# SPGSS1_1.0 register map
Vendor: Texas Instruments
Registers are 32-bit, read-write, no defined reset value unless marked. A register's access mark holds for its fields unless they carry their own. Offsets are as the file gives them; [hi:lo] are bit positions; lines under a group give offsets from that group; {n}, {i} and the like mark numbered series; 'fields as' and 'values as' point back to an identical list; <NAME> marks a mode.

## SPGSS1 (part 8 of 8)
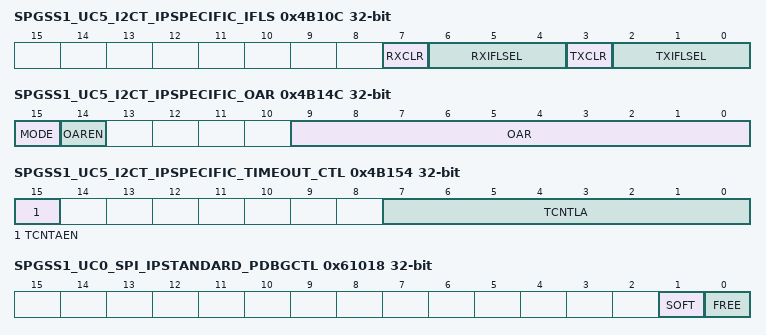
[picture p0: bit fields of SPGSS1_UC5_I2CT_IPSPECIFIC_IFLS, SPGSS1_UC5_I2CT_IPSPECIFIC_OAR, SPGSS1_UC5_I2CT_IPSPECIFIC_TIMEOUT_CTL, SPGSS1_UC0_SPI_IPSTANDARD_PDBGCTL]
0x4B10C SPGSS1_UC5_I2CT_IPSPECIFIC_IFLS — Interrupt FIFO Level Select Register
  [7] RXCLR — RX FIFO CLEAR. Setting this bit will clear the RX FIFO contents.
    0=DISABLE (Disable FIFO clear); 1=ENABLE (Enable FIFO Clear)
  [6:4] RXIFLSEL — FIFO Level Select for generating events (interrupt/dma). Note: for undefined settings the default configuration is used.
    1=LVL_1_4 (RX FIFO >= 1/4 full); 2=LVL_1_2 (RX FIFO >= 1/2 full (default)); 3=LVL_3_4 (RX FIFO >= 3/4 full); 4=LVL_NOT_EMPTY (Opposite of empty); 5=LVL_FULL (RX FIFO is full); 6=LVL_ALMOST_FULL (RX_FIFO >= (MAX_FIFO_LEN -1)); 7=LVL_ALMOST_EMPTY (RX_FIFO <= 1)
  [3] TXCLR — TX FIFO CLEAR. Setting this bit will clear the TX FIFO contents.
    0=DISABLE (Disable FIFO clear); 1=ENABLE (Enable FIFO Clear)
  [2:0] TXIFLSEL — FIFO Level Select for generating events (interrupt/dma). Note: for undefined settings the default configuration is used.
    1=LVL_3_4 (TX FIFO <= 3/4 empty); 2=LVL_1_2 (TX FIFO <= 1/2 empty (default)); 3=LVL_1_4 (TX FIFO <= 1/4 empty); 4=LVL_NOT_FULL (Opposite of full); 5=LVL_EMPTY (TX FIFO is empty); 6=LVL_ALMOST_EMPTY (TX FIFO <= 1); 7=LVL_ALMOST_FULL (TX_FIFO >= (MAX_FIFO_LEN -1))
0x4B118 SPGSS1_UC5_I2CT_IPSPECIFIC_GFCTL — I2C Glitch Filter Control
  [2:0] DGFSEL — Glitch Suppression Pulse Width This field controls the pulse width select for glitch suppression on the SCL and SDA lines. The following values are the glitch suppression values in terms of functional clocks. (Core Domain only)
    0=DISABLED (Bypass); 1=CLK_1 (1 clock); 2=CLK_2 (2 clocks); 3=CLK_3 (3 clocks); 4=CLK_4 (4 clocks); 5=CLK_8 (8 clocks); 6=CLK_16 (16 clocks); 7=CLK_31 (31 clocks)
0x4B120 SPGSS1_UC5_I2CT_IPSPECIFIC_TTXDATA — I2C TXData
  [7:0] DATA — Transmit Data This byte contains the data to be transferred during the next transaction.
    0=MINIMUM (Smallest value); 255=MAXIMUM (Highest possible value)
0x4B124 SPGSS1_UC5_I2CT_IPSPECIFIC_RXDATA ro — I2C RXData
  [7:0] DATA — Received Data. This field contains the last received data.
    values as SPGSS1_UC5_I2CT_IPSPECIFIC_TTXDATA.DATA
0x4B14C SPGSS1_UC5_I2CT_IPSPECIFIC_OAR — I2C Own Address
  [15] MODE — This bit selects the adressing mode to be used. When 0, 7-bit addressing is used. When 1, 10-bit addressing is used.
    0=Enable 7-bit addressing; 1=Enable 10-bit addressing
  [14] OAREN — Own Address Enable
    0=DISABLE (Disable OAR address); 1=ENABLE (Enable OAR address)
  [9:0] OAR — Own Address: This field specifies bits A9 through A0 of the Target address. In 7-bit addressing mode as selected by I2CSOAR.MODE bit, the top 3 bits are don't care
    0=MINIMUM (Smallest value); 0x3FF=MAXIMUM (Highest possible value)
0x4B150 SPGSS1_UC5_I2CT_IPSPECIFIC_TIMEOUT_CNT ro — I2C Timeout Count Register
  [7:0] TCNTA — Timeout Count A Current Count: This field contains the upper 8 bits of a 12-bit current counter for timeout counter A
    0=MINIMUM (Smallest Value); 255=MAXIMUM (Highest possible value)
0x4B154 SPGSS1_UC5_I2CT_IPSPECIFIC_TIMEOUT_CTL — I2C Timeout Count Control Register
  [15] TCNTAEN — Timeout Counter A Enable
    0=DISABLE (Disable Timeout Counter B); 1=ENABLE (Enable Timeout Counter B)
  [7:0] TCNTLA — Timeout counter A load value Counter A is used for SCL low detection. This field contains the upper 8 bits of a 12-bit pre-load value for the Timeout A count. NOTE: The value of CNTLA must be greater than 1h. Each count is equal to 520 times the timeout period of functional clock. For example, with 8MHz functional clock and a 100KHz operating I2C clock, one timeout period will be equal to (1 / 8MHz) * 520 or 65 us.
    values as SPGSS1_UC5_I2CT_IPSPECIFIC_TIMEOUT_CNT.TCNTA
0x4BE00 SPGSS1_UC5_I2CT_LMGMT_DFT_ATRT_TEST0 — Test 0 register
  [4:0] DTB_MUX_SEL — This bit field is used to select DTB mux digital output signals.
    0=DISABLE (Disables DTB MUX); {v}=GRP{v} (Selects test group {v}) (v=1..7)
0x61000 SPGSS1_UC0_SPI_IPSTANDARD_CLKDIV — Clock Divider
  [2:0] RATIO — Selects divide ratio of module clock
    0=DIV_BY_1 (Do not divide clock source); {v}=DIV_BY_{v+1} (Divide clock source by {v+1}) (v=1..7)
0x61008 SPGSS1_UC0_SPI_IPSTANDARD_CLKSEL — Clock Select for Ultra Low Power peripherals
  [3] BUSCLK_SEL — Selects buscclk as clock source if enabled
    0=DISABLE (Does not select this clock as a source); 1=ENABLE (Select this clock as a source)
0x61018 SPGSS1_UC0_SPI_IPSTANDARD_PDBGCTL — Peripheral Debug Control
  [1] SOFT — Soft halt boundary control. This function is only available, if [FREE] is set to 'STOP'
    0=DEPRECATED (Not supported); 1=DELAYED (The peripheral blocks the debug freeze until it has reached a boundary where it can resume without corruption)
  [0] FREE — Free run control
    0=STOP (The peripheral freezes functionality while the Core Halted input is asserted and resumes when it is deasserted.); 1=RUN (The peripheral ignores the state of the Core Halted input)
0x61020 SPGSS1_UC0_SPI_IPSTANDARD_CPU_INT group
  0x00 SPGSS1_UC0_SPI_IPSTANDARD_IIDX ro — Interrupt Index Register
    [7:0] STAT — Interrupt index status
      0=NO_INTR (No interrupt pending); 1=PER_EVT (Transmit Parity Event/interrupt pending); 2=RXFIFO_OFV_EVT (RX FIFO Overflow Event/interrupt pending); 3=RX_EVT (Receive interrupt); 4=RXFULL_EVT (RX FIFO Full Interrupt); 5=TXFIFO_UNF_EVT (TX FIFO underflow interrupt); 6=TX_EVT (Transmit Event); 7=TX_EMPTY (Transmit Buffer Empty Event/interrupt pending); 9=IDLE_EVT (End of Transmit Event/interrupt pending); 10=RTOUT_EVT (SPI receive time-out interrupt); 16=DMA_DONE_RX (DMA DONE on RX); 17=DMA_DONE_TX (DMA DONE on TX); 19=DMA_PREIRQ_RX (DMA PRE IRQ RX INTERRUPT); 20=DMA_PREIRQ_TX (DMA PRE IRQ TX INTERRUPT); 21=LTOUT (SPI line time-out interrupt)
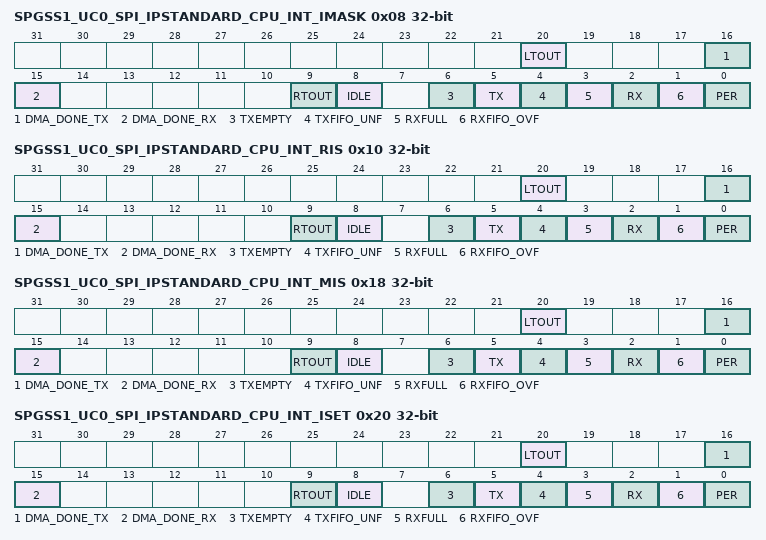
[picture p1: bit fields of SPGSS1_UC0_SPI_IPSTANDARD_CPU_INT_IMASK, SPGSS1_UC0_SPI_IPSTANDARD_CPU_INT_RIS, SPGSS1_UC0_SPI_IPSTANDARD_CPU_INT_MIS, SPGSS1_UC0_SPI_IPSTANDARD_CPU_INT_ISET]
  0x08 SPGSS1_UC0_SPI_IPSTANDARD_CPU_INT_IMASK — Interrupt mask
    [20] LTOUT — Enable SPI Line Time-Out event mask.
      0=CLR (Clear Interrupt Mask); 1=SET (Set Interrupt Mask)
    [16] DMA_DONE_TX — Enable DMA Done on TX Event Channel Interrupt
      0=CLR (Interrupt disabled); 1=SET (Set Interrupt Mask)
    [15] DMA_DONE_RX — Enable DMA Done on RX Event Channel Interrupt
      0=CLR (Interrupt disabled); 1=SET (Set Interrupt Mask)
    [9] RTOUT — Enable SPI Receive Time-Out event mask.
      0=CLR (Clear Interrupt Mask); 1=SET (Set Interrupt Mask)
    [8] IDLE — SPI Idle event mask.
      0=CLR (Clear Interrupt Mask); 1=SET (Set Interrupt Mask)
    [6] TXEMPTY — Transmit FIFO Empty event mask.
      0=CLR (Clear Interrupt Mask); 1=SET (Set Interrupt Mask)
    [5] TX — Mask Transmit Event
      0=CLR (Clear Interrupt Mask); 1=SET (Set Interrupt Mask)
    [4] TXFIFO_UNF — TX FIFO underflow interrupt mask
      0=CLR (Clear Interrupt Mask); 1=SET (Set Interrupt Mask)
    [3] RXFULL — RX FIFO Full Interrupt Mask
      0=CLR (Clear Interrupt Mask); 1=SET (Set Interrupt Mask)
    [2] RX — Mask Receive Event
      0=CLR (Clear Interrupt Mask); 1=SET (Set Interrupt Mask)
    [1] RXFIFO_OVF — RXFIFO overflow event mask.
      0=CLR (Clear Interrupt Mask); 1=SET (Set Interrupt Mask)
    [0] PER — Parity error event mask.
      0=CLR (Clear Interrupt Mask); 1=SET (Set Interrupt Mask)
  0x10 SPGSS1_UC0_SPI_IPSTANDARD_CPU_INT_RIS — Raw interrupt status
    [20] LTOUT — SPI Line Time-Out event. This bit is set after timeout period has lapsed
      0=CLR (Interrupt did not occur); 1=SET (Interrupt occurred)
    [16] DMA_DONE_TX — DMA Done on TX Event Channel Interrupt
      0=CLR (Interrupt disabled); 1=SET (Interrupt occured)
    [15] DMA_DONE_RX — DMA Done on RX Event Channel Interrupt
      0=CLR (Interrupt disabled); 1=SET (Interrupt occured)
    [9] RTOUT — SPI Receive Time-Out event. This bit is set when there is still contents in the FIFO after the timeout period
      0=CLR (Interrupt did not occur); 1=SET (Interrupt occurred)
    [8] IDLE — SPI has done finished transfers and changed into IDLE mode. This bit is set when BUSY goes low.
      0=CLR (Interrupt did not occur); 1=SET (Interrupt occurred)
    [6] TXEMPTY — Transmit FIFO Empty interrupt mask. This interrupt is set if all data in the Transmit FIFO have been move to the shift register.
      0=CLR (Interrupt did not occur); 1=SET (Interrupt occurred)
    [5] TX — Transmit event When FIFO is present, this bit is set when Tx FIFO threshold is reached When FIFO is not present, this bit is set when tx buffer is empty
      0=CLR (Interrupt did not occur); 1=SET (Interrupt occurred)
    [4] TXFIFO_UNF — TX FIFO Underflow Interrupt
      0=CLR (Interrupt did not occur); 1=SET (Interrupt occurred)
    [3] RXFULL — RX FIFO Full Interrupt
      0=CLR (Interrupt did not occur); 1=SET (Interrupt occurred)
    [2] RX — Receive event When FIFO is present, this bit is set when FIFO threshold is reached When FIFO is not present, this bit is set when a frame is received
      0=CLR (Interrupt did not occur); 1=SET (Interrupt occurred)
    [1] RXFIFO_OVF — RXFIFO overflow event. This interrupt is set if an RX FIFO overflow has been detected.
      0=CLR (Interrupt did not occur); 1=SET (Interrupt occurred)
    [0] PER — Parity error event: this bit is set if a Parity error has been detected
      0=CLR (Interrupt did not occur); 1=SET (Interrupt occurred)
  0x18 SPGSS1_UC0_SPI_IPSTANDARD_CPU_INT_MIS — Masked interrupt status
    [20] LTOUT — Masked SPI Line Time-Out Interrupt.
      0=CLR (Clear Interrupt Mask); 1=SET (Set Interrupt Mask)
    [16] DMA_DONE_TX — Masked DMA Done on TX Event Channel Interrupt
      0=CLR (Interrupt did not occur); 1=SET (Interrupt occured)
    [15] DMA_DONE_RX — Masked DMA Done on RX Event Channel Interrupt
      0=CLR (Interrupt did not occur); 1=SET (Interrupt occured)
    [9] RTOUT — Masked SPI Receive Time-Out Interrupt.
      0=CLR (Clear Interrupt Mask); 1=SET (Set Interrupt Mask)
    [8] IDLE — Masked SPI IDLE mode event.
      0=CLR (Interrupt did not occur); 1=SET (Interrupt occurred)
    [6] TXEMPTY — Masked Transmit FIFO Empty event.
      0=CLR (Interrupt did not occur); 1=SET (Interrupt occurred)
    [5] TX — Masked Transmit FIFO event. This interrupt is set if the selected Transmit FIFO level has been reached.
      0=CLR (Interrupt did not occur); 1=SET (Interrupt occurred)
    [4] TXFIFO_UNF — TX FIFO underflow interrupt
      0=CLR (Interrupt did not occur); 1=SET (Interrupt occurred)
    [3] RXFULL — RX FIFO Full Interrupt
      0=CLR (Interrupt did not occur); 1=SET (Interrupt occurred)
    [2] RX — Masked Receive Event
      0=CLR (Interrupt did not occur); 1=SET (Interrupt occurred)
    [1] RXFIFO_OVF — Masked RXFIFO overflow event. This interrupt is set if an RX FIFO overflow has been detected.
      0=CLR (Interrupt did not occur); 1=SET (Interrupt occurred)
    [0] PER — Masked Parity error event: this bit if a Parity error has been detected
      0=CLR (Interrupt did not occur); 1=SET (Interrupt occurred)
  0x20 SPGSS1_UC0_SPI_IPSTANDARD_CPU_INT_ISET — Interrupt set
    [20] LTOUT — Set SPI Line Time-Out Event.
      0=NO_EFFECT (Writing 0 has no effect); 1=SET (Set Interrupt Mask)
    [16] DMA_DONE_TX — Set DMA Done on TX Event Channel Interrupt
      0=NO_EFFECT (Interrupt disabled); 1=SET (Set Interrupt)
    [15] DMA_DONE_RX — Set DMA Done on RX Event Channel Interrupt
      0=NO_EFFECT (Interrupt disabled); 1=SET (Set Interrupt)
    [9] RTOUT — Set SPI Receive Time-Out Event.
      values as LTOUT
    [8] IDLE — Set SPI IDLE mode event.
      0=NO_EFFECT (Writing 0 has no effect); 1=SET (Set Interrupt)
    [6] TXEMPTY — Set Transmit FIFO Empty event.
      0=NO_EFFECT (Writing 0 has no effect); 1=SET (Set Interrupt)
    [5] TX — Set Transmit event.
      0=NO_EFFECT (Writing 0 has no effect); 1=SET (Set Interrupt)
    [4] TXFIFO_UNF — Set TX FIFO Underflow Event
      0=NO_EFFECT (Writing has no effect); 1=SET (Set interrupt)
    [3] RXFULL — Set RX FIFO Full Event
      0=NO_EFFECT (Writing has no effect); 1=SET (Set Interrupt)
    [2] RX — Set Receive event.
      0=NO_EFFECT (Writing 0 has no effect); 1=SET (Set Interrupt)
    [1] RXFIFO_OVF — Set RXFIFO overflow event.
      0=NO_EFFECT (Writing 0 has no effect); 1=SET (Set Interrupt)
    [0] PER — Set Parity error event.
      0=NO_EFFECT (Writing 0 has no effect); 1=SET (Set Interrupt)
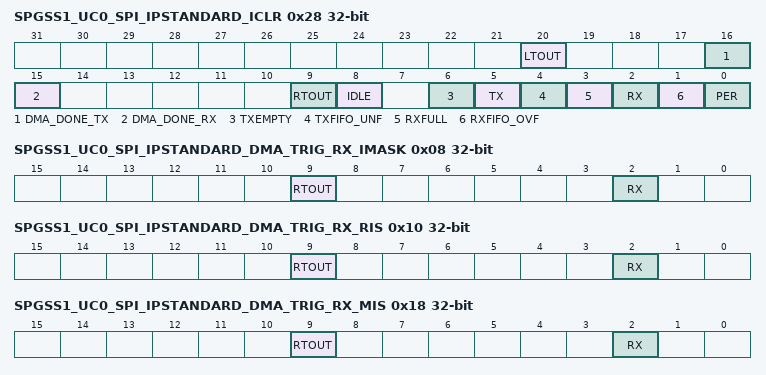
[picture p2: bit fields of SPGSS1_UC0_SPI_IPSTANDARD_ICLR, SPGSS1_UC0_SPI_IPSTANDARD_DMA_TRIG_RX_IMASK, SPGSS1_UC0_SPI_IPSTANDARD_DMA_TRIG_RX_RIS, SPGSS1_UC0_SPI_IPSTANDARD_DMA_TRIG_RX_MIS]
  0x28 SPGSS1_UC0_SPI_IPSTANDARD_ICLR — Interrupt clear
    [20] LTOUT — Clear SPI Line Time-Out Event.
      0=NO_EFFECT (Writing 0 has no effect); 1=CLR (Set Interrupt Mask)
    [16] DMA_DONE_TX — Clear DMA Done on TX Event Channel Interrupt
      0=NO_EFFECT (Interrupt disabled); 1=CLR (Clear Interrupt)
    [15] DMA_DONE_RX — Clear DMA Done on RX Event Channel Interrupt
      0=NO_EFFECT (Interrupt disabled); 1=CLR (Clear Interrupt)
    [9] RTOUT — Clear SPI Receive Time-Out Event.
      values as LTOUT
    [8] IDLE — Clear SPI IDLE mode event.
      0=NO_EFFECT (Writing 0 has no effect); 1=CLR (Clear Interrupt)
    [6] TXEMPTY — Clear Transmit FIFO Empty event.
      values as IDLE
    [5] TX — Clear Transmit event.
      values as IDLE
    [4] TXFIFO_UNF — Clear TXFIFO underflow event
      0=NO_EFFECT (Writing has no effect); 1=CLR (Clear interrupt)
    [3] RXFULL — Clear RX FIFO underflow event
      0=NO_EFFECT (Writing has no effect); 1=CLR (Clear interrupt)
    [2] RX — Clear Receive event.
      values as IDLE
    [1] RXFIFO_OVF — Clear RXFIFO overflow event.
      values as IDLE
    [0] PER — Clear Parity error event.
      values as IDLE
0x61050 SPGSS1_UC0_SPI_IPSTANDARD_DMA_TRIG_RX group
  0x08 SPGSS1_UC0_SPI_IPSTANDARD_DMA_TRIG_RX_IMASK — Interrupt mask
    [9] RTOUT — SPI Receive Time-Out event mask.
      0=CLR (Clear Interrupt Mask); 1=SET (Set Interrupt Mask)
    [2] RX — Receive FIFO event mask.
      0=CLR (Clear Interrupt Mask); 1=SET (Set Interrupt Mask)
  0x10 SPGSS1_UC0_SPI_IPSTANDARD_DMA_TRIG_RX_RIS — Raw interrupt status
    [9] RTOUT — SPI Receive Time-Out Event. This bit is set when there is still contents in the FIFO after the timeout period
      0=CLR (Clear Interrupt Mask); 1=SET (Set Interrupt Mask)
    [2] RX — Receive FIFO event.This interrupt is set if the selected Receive FIFO level has been reached
      0=CLR (Interrupt did not occur); 1=SET (Interrupt occurred)
  0x18 SPGSS1_UC0_SPI_IPSTANDARD_DMA_TRIG_RX_MIS — Masked interrupt status
    [9] RTOUT — SPI Receive Time-Out event mask.
      0=CLR (Clear Interrupt Mask); 1=SET (Set Interrupt Mask)
    [2] RX — Receive FIFO event mask.
      0=CLR (Interrupt did not occur); 1=SET (Interrupt occurred)
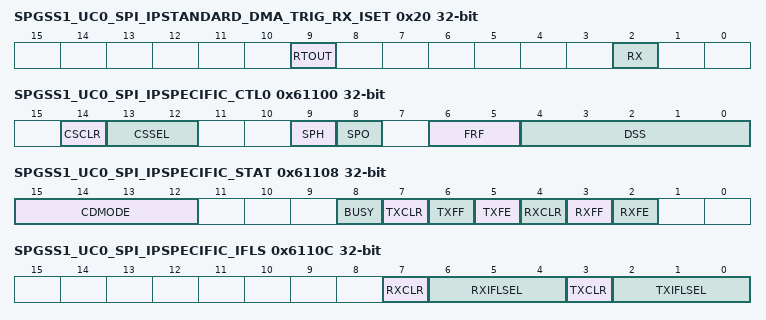
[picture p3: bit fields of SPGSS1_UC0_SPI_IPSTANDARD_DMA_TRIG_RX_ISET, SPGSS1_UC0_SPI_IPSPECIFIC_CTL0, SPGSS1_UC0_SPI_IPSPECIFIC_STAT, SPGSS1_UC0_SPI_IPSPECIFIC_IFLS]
  0x20 SPGSS1_UC0_SPI_IPSTANDARD_DMA_TRIG_RX_ISET — Interrupt set
    [9] RTOUT — Set SPI Receive Time-Out event.
      values as SPGSS1_UC0_SPI_IPSTANDARD_CPU_INT.SPGSS1_UC0_SPI_IPSTANDARD_CPU_INT_ISET.LTOUT
    [2] RX — Set Receive FIFO event.
      0=NO_EFFECT (Writing 0 has no effect); 1=SET (Set Interrupt)
0x61080 SPGSS1_UC0_SPI_IPSTANDARD_DMA_TRIG_TX group
  0x08 SPGSS1_UC0_SPI_IPSTANDARD_DMA_TRIG_TX_IMASK — Interrupt mask
    [5] TX — Transmit FIFO event mask.
      0=CLR (Clear Interrupt Mask); 1=SET (Set Interrupt Mask)
  0x10 SPGSS1_UC0_SPI_IPSTANDARD_DMA_TRIG_TX_RIS — Raw interrupt status
    [5] TX — Transmit FIFO event: A read returns the current mask for transmit FIFO interrupt. On a write of 1, the mask for transmit FIFO interrupt is set which means the interrupt state will be reflected in MIS.TXMIS. A write of 0 clears the mask which means MIS.TXMIS will not reflect the interrupt.
      0=CLR (Interrupt did not occur); 1=SET (Interrupt occurred)
  0x18 SPGSS1_UC0_SPI_IPSTANDARD_DMA_TRIG_TX_MIS — Masked interrupt status
    [5] TX — Masked Transmit FIFO event
      0=CLR (Interrupt did not occur); 1=SET (Interrupt occurred)
  0x20 SPGSS1_UC0_SPI_IPSTANDARD_DMA_TRIG_TX_ISET — Interrupt set
    [5] TX — Set Transmit FIFO event.
      0=NO_EFFECT (Writing 0 has no effect); 1=SET (Set Interrupt)
0x610E4 SPGSS1_UC0_SPI_IPSTANDARD_INTCTL — Interrupt control register
  [0] INTEVAL — Writing a 1 to this field re-evaluates the interrupt sources.
    0=DISABLE (The interrupt or event line is disabled.); 1=EVAL (The interrupt or event line is in software mode. Software must clear the RIS.)
0x61100 SPGSS1_UC0_SPI_IPSPECIFIC_CTL0 — SPI control register 0
  [14] CSCLR — Clear shift register counter on CS inactive This bit is relevant only in the peripheral, CTL1.CP=0.
    0=DISABLE (Disable automatic clear of shift register when CS goes to disable.); 1=ENABLE (Enable automatic clear of shift register when CS goes to disable.)
  [13:12] CSSEL — Select the CS line to control on data transfer This bit is applicable for both controller/target mode
    {v}=CS line select: {v} (v=0..3)
  [9] SPH — CLKOUT phase (Motorola SPI frame format only) This bit selects the clock edge that captures data and enables it to change state. It has the most impact on the first bit transmitted by either permitting or not permitting a clock transition before the first data capture edge.
    0=FIRST (Data is captured on the first clock edge transition.); 1=SECOND (Data is captured on the second clock edge transition.)
  [8] SPO — CLKOUT polarity (Motorola SPI frame format only)
    0=LOW (SPI produces a steady state LOW value on the CLKOUT); 1=HIGH (SPI produces a steady state HIGH value on the CLKOUT)
  [6:5] FRF — Frame format Select
    0=MOTOROLA_3WIRE (Motorola SPI frame format (3 wire mode)); 1=MOTOROLA_4WIRE (Motorola SPI frame format (4 wire mode)); 2=TI_SYNC (TI synchronous serial frame format)
  [4:0] DSS — Data Size Select. Values 0 - 2 are reserved and shall not be used. 3h = 4_BIT : 4-bit data SPI allows only values up to 16 Bit
    {v}=Data Size Select bits: {v+1} (v=3..15)
0x61108 SPGSS1_UC0_SPI_IPSPECIFIC_STAT access per field — Status Register
  [15:12] CDMODE ro — Current CDMODE status. This reflects the current counter counter value.
    0=MINIMUM (Smallest value); 0=DATA (Manual mode: Data); 15=MAXIMUM (Highest possible value); 15=COMMAND (Manual mode: Command)
  [8] BUSY rw
    0=IDLE (SPI is in idle mode.); 1=ACTIVE (SPI is currently transmitting and/or receiving data)
  [7] TXCLR ro — TX FIFO Clear Status
    0=CLEARED (FIFO is not cleared); 1=SET (FIFO clear is complete)
  [6] TXFF ro — Transmit FIFO Full The meaning of this bit depends on the state of the FEN bit in the CTL0 register.
    0=CLEARED (The transmitter is not full.); 1=SET (If the FIFO is disabled (FEN is 0), the transmit holding register is full. If the FIFO is enabled (FEN is 1), the transmit FIFO is full.)
  [5] TXFE rw — Transmit FIFO empty.
    0=NOT_EMPTY (Transmit FIFO is not empty.); 1=EMPTY (Transmit FIFO is empty.)
  [4] RXCLR ro — RX FIFO Clear Status
    values as TXCLR
  [3] RXFF ro — Receive FIFO Full The meaning of this bit depends on the state of the FEN bit in the CTL0 register.
    0=CLEARED (The receiver can receive data.); 1=SET (If the FIFO is disabled (FEN is 0), the receive holding register is full. If the FIFO is enabled (FEN is 1), the receive FIFO is full.)
  [2] RXFE rw — Receive FIFO empty.
    0=NOT_EMPTY (Receive FIFO is not empty.); 1=EMPTY (Receive FIFO is empty.)
0x6110C SPGSS1_UC0_SPI_IPSPECIFIC_IFLS — Interrupt FIFO Level Select Register
  fields as SPGSS1_UC5_I2CT_IPSPECIFIC_IFLS
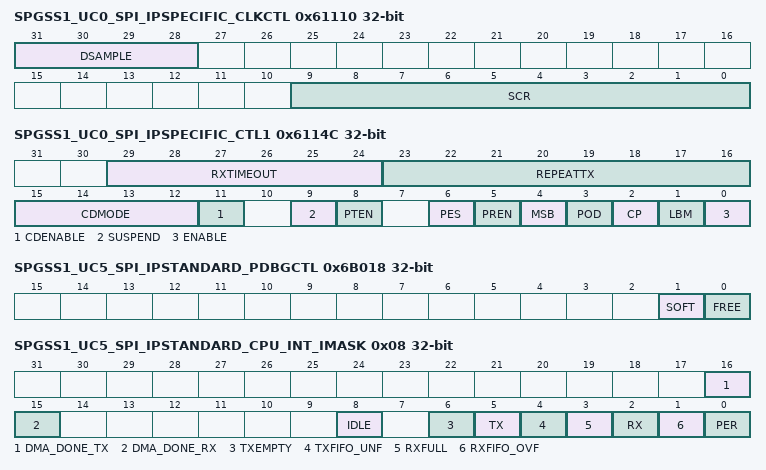
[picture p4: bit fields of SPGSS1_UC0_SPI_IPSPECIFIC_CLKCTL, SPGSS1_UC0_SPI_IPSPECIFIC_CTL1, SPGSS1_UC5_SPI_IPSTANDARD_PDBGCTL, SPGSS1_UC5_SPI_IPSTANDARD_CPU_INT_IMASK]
0x61110 SPGSS1_UC0_SPI_IPSPECIFIC_CLKCTL — Clock prescaler and divider register.
  [31:28] DSAMPLE — Delayed sampling value. In controller mode the data on the input pin will be delayed sampled by the defined clock cycles of internal functional clock hence relaxing the setup time of input data. This setting is useful in systems where the board delays and external peripheral delays are more than the input setup time of the controller. Please refer to the datasheet for values of controller input setup time and assess what DSAMPLE value meets the requirement of the system. Note: High values of DSAMPLE can cause HOLD time violations and must be factored in the calculations.
    0=MINIMUM (Smallest value); 15=MAXIMUM (Highest possible value)
  [9:0] SCR — Serial clock divider: This is used to generate the transmit and receive bit rate of the SPI. The SPI bit rate is (SPI's functional clock frequency)/((SCR+1)*2). SCR is a value from 0-1023.
    values as SPGSS1_UC5_I2CT_IPSPECIFIC_OAR.OAR
0x61120 SPGSS1_UC0_SPI_IPSPECIFIC_TXDATA — TXDATA Register
  [15:0] DATA — Transmit Data When read, last written value will be returned. If the last write to this field was a 32-bit write (with PACKEN=1), 32-bits will be returned and if the last write was a 16-bit write (PACKEN=0), those 16-bits will be returned. When written, one or two FIFO entries will be written depending on PACKEN value. Data values are removed from the transmit FIFO one value at a time by the transmit logic. It is loaded into the transmit serial shifter, then serially shifted out onto the TXD output pin at the programmed bit rate. When a data size of less than 16 bits is selected, the user must right-justify data written to the transmit FIFO. The transmit logic ignores the unused bits.
0x61124 SPGSS1_UC0_SPI_IPSPECIFIC_RXDATA ro — RXDATA Register
  [15:0] DATA — Received Data When PACKEN=1,two entries of the FIFO are returned as a 32-bit value. When PACKEN=0, 1 entry of FIFO is returned as 16-bit value. As data values are removed by the receive logic from the incoming data frame, they are placed into the entry in the receive FIFO, pointed to by the current FIFO write pointer. Received data less than 16 bits is automatically right justified in the receive buffer.
0x6114C SPGSS1_UC0_SPI_IPSPECIFIC_CTL1 — SPI control register 1
  [29:24] RXTIMEOUT — Receive Timeout (only for Peripheral mode) Defines the number of Clock Cycles before after which the Receive Timeout flag RTOUT is set. The time is calculated using the control register for the clock selection and divider in the Controller mode configuration. A value of 0 disables this function.
    0=MINIMUM (Smallest value); 63=MAXIMUM (Highest possible value)
  [23:16] REPEATTX — Counter to repeat last transfer 0: repeat last transfer is disabled. x: repeat the last transfer with the given number. The transfer will be started with writing a data into the TX Buffer. Sending the data will be repeated with the given value, so the data will be transferred X+1 times in total. The behavior is identical as if the data would be written into the TX Buffer that many times as defined by the value here. It can be used to clean a transfer or to pull a certain amount of data by a peripheral.
    0=DISABLE (REPEATTX disable); 0=MINIMUM (Smallest value); 255=MAXIMUM (Highest possible value)
  [15:12] CDMODE — Command/Data Mode Value When CTL1.CDENABLE is 1, CS3 line is used as C/D signal to distinguish between Command (C/D low) and Data (C/D high) information. When a value is written into the CTL1.CDMODE bits, the C/D (CS3) line will go low for the given numbers of byte which are sent by the SPI, starting with the next value to be transmitted after which, C/D line will go high automatically 0: Manual mode with C/D signal as High 1-14: C/D is low while this number of bytes are being sent after which, this field sets to 0 and C/D goes high. Reading this field at any time returns the remaining number of command bytes. 15: Manual mode with C/D signal as Low.
    values as SPGSS1_UC0_SPI_IPSPECIFIC_STAT.CDMODE
  [11] CDENABLE — Command/Data Mode enable
    0=DISABLE (CS3 is used for Chip Select); 1=ENABLE (CS3 is used as CD signal)
  [9] SUSPEND — Suspend external communication
    0=DISABLE (Functional mode resumed); 1=ENABLE (External communication suspended)
  [8] PTEN — Parity transmit enable If enabled, parity transmission will be done for both controller and peripheral modes.
    0=DISABLE (Parity transmission is disabled); 1=ENABLE (Parity transmission is enabled)
  [6] PES — Even Parity Select
    0=DISABLE (Odd Parity mode); 1=ENABLE (Even Parity mode)
  [5] PREN — Parity receive enable If enabled, parity reception check will be done for both controller and peripheral modes In case of a parity miss-match the parity error flag RIS.PER will be set.
    0=DISABLE (Disable Parity receive function); 1=ENABLE (Enable Parity receive function)
  [4] MSB — MSB first select. Controls the direction of the receive and transmit shift register.
    0=DISABLE (LSB first); 1=ENABLE (MSB first)
  [3] POD — Peripheral-mode: Data output disabled This bit is relevant only in Peripheral mode. In multiple-peripheral system topologies, SPI controller can broadcast a message to all peripherals, while only one peripheral drives the line. POD can be used by the SPI peripheral to disable driving data on the line.
    0=DISABLE (SPI can drive the POCI output in peripheral mode.); 1=ENABLE (SPI cannot drive the POCI output in peripheral mode.)
  [2] CP — Controller or peripheral mode select. This bit can be modified only when SPI is disabled, CTL1.ENABLE=0.
    0=DISABLE (Select Peripheral mode); 1=ENABLE (Select Controller Mode)
  [1] LBM — Loop back mode
    0=DISABLE (Disable loopback mode); 1=ENABLE (Enable loopback mode)
  [0] ENABLE — SPI enable
    0=DISABLE (Disable module function); 1=ENABLE (Enable module function)
0x61E00 SPGSS1_UC0_SPI_LMGMT_DFT_ATRT_TEST0 — Test 0 Register
  [3:0] DTB_MUX_SEL — This bit field is used to select DTB mux digital output signals.
    0=DISABLE (Disables DTB MUX); {v}=GRP{v} (Selects test group {v}) (v=1..9)
0x6B000 SPGSS1_UC5_SPI_IPSTANDARD_CLKDIV — Clock Divider
  fields as SPGSS1_UC0_SPI_IPSTANDARD_CLKDIV
0x6B008 SPGSS1_UC5_SPI_IPSTANDARD_CLKSEL — Clock Select for Ultra Low Power peripherals
  fields as SPGSS1_UC0_SPI_IPSTANDARD_CLKSEL
0x6B018 SPGSS1_UC5_SPI_IPSTANDARD_PDBGCTL — Peripheral Debug Control
  fields as SPGSS1_UC0_SPI_IPSTANDARD_PDBGCTL
0x6B020 SPGSS1_UC5_SPI_IPSTANDARD_CPU_INT group
  0x00 SPGSS1_UC5_SPI_IPSTANDARD_IIDX ro — Interrupt Index Register
    fields as SPGSS1_UC0_SPI_IPSTANDARD_CPU_INT.SPGSS1_UC0_SPI_IPSTANDARD_IIDX
  0x08 SPGSS1_UC5_SPI_IPSTANDARD_CPU_INT_IMASK — Interrupt mask
    [16] DMA_DONE_TX — Enable DMA Done on TX Event Channel Interrupt
      0=CLR (Interrupt disabled); 1=SET (Set Interrupt Mask)
    [15] DMA_DONE_RX — Enable DMA Done on RX Event Channel Interrupt
      0=CLR (Interrupt disabled); 1=SET (Set Interrupt Mask)
    [8] IDLE — SPI Idle event mask.
      0=CLR (Clear Interrupt Mask); 1=SET (Set Interrupt Mask)
    [6] TXEMPTY — Transmit FIFO Empty event mask.
      0=CLR (Clear Interrupt Mask); 1=SET (Set Interrupt Mask)
    [5] TX — Mask Transmit Event
      0=CLR (Clear Interrupt Mask); 1=SET (Set Interrupt Mask)
    [4] TXFIFO_UNF — TX FIFO underflow interrupt mask
      0=CLR (Clear Interrupt Mask); 1=SET (Set Interrupt Mask)
    [3] RXFULL — RX FIFO Full Interrupt Mask
      0=CLR (Clear Interrupt Mask); 1=SET (Set Interrupt Mask)
    [2] RX — Mask Receive Event
      0=CLR (Clear Interrupt Mask); 1=SET (Set Interrupt Mask)
    [1] RXFIFO_OVF — RXFIFO overflow event mask.
      0=CLR (Clear Interrupt Mask); 1=SET (Set Interrupt Mask)
    [0] PER — Parity error event mask.
      0=CLR (Clear Interrupt Mask); 1=SET (Set Interrupt Mask)
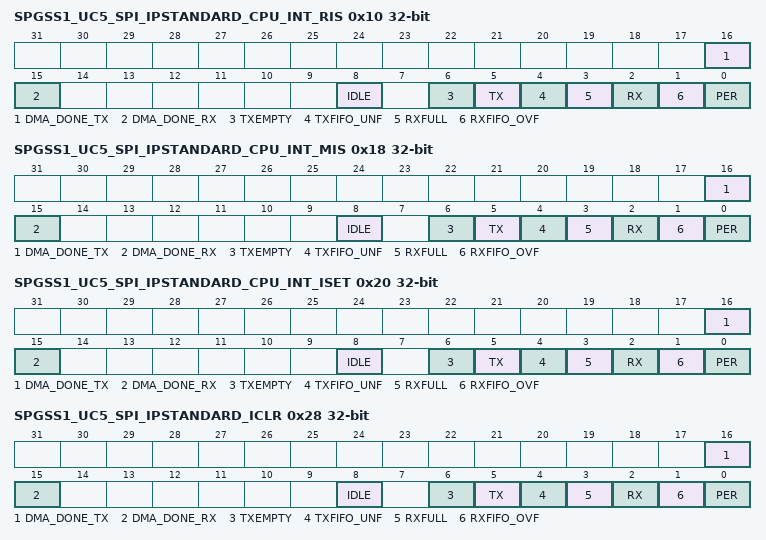
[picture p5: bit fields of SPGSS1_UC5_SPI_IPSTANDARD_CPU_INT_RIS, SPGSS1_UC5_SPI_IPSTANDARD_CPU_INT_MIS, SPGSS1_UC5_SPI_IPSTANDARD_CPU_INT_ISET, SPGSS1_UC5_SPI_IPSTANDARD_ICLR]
  0x10 SPGSS1_UC5_SPI_IPSTANDARD_CPU_INT_RIS — Raw interrupt status
    [16] DMA_DONE_TX — DMA Done on TX Event Channel Interrupt
      0=CLR (Interrupt disabled); 1=SET (Interrupt occured)
    [15] DMA_DONE_RX — DMA Done on RX Event Channel Interrupt
      0=CLR (Interrupt disabled); 1=SET (Interrupt occured)
    [8] IDLE — SPI has done finished transfers and changed into IDLE mode. This bit is set when BUSY goes low.
      0=CLR (Interrupt did not occur); 1=SET (Interrupt occurred)
    [6] TXEMPTY — Transmit FIFO Empty interrupt mask. This interrupt is set if all data in the Transmit FIFO have been move to the shift register.
      0=CLR (Interrupt did not occur); 1=SET (Interrupt occurred)
    [5] TX — Transmit event When FIFO is present, this bit is set when Tx FIFO threshold is reached When FIFO is not present, this bit is set when tx buffer is empty
      0=CLR (Interrupt did not occur); 1=SET (Interrupt occurred)
    [4] TXFIFO_UNF — TX FIFO Underflow Interrupt
      0=CLR (Interrupt did not occur); 1=SET (Interrupt occurred)
    [3] RXFULL — RX FIFO Full Interrupt
      0=CLR (Interrupt did not occur); 1=SET (Interrupt occurred)
    [2] RX — Receive event When FIFO is present, this bit is set when FIFO threshold is reached When FIFO is not present, this bit is set when a frame is received
      0=CLR (Interrupt did not occur); 1=SET (Interrupt occurred)
    [1] RXFIFO_OVF — RXFIFO overflow event. This interrupt is set if an RX FIFO overflow has been detected.
      0=CLR (Interrupt did not occur); 1=SET (Interrupt occurred)
    [0] PER — Parity error event: this bit is set if a Parity error has been detected
      0=CLR (Interrupt did not occur); 1=SET (Interrupt occurred)
  0x18 SPGSS1_UC5_SPI_IPSTANDARD_CPU_INT_MIS — Masked interrupt status
    [16] DMA_DONE_TX — Masked DMA Done on TX Event Channel Interrupt
      0=CLR (Interrupt did not occur); 1=SET (Interrupt occured)
    [15] DMA_DONE_RX — Masked DMA Done on RX Event Channel Interrupt
      0=CLR (Interrupt did not occur); 1=SET (Interrupt occured)
    [8] IDLE — Masked SPI IDLE mode event.
      0=CLR (Interrupt did not occur); 1=SET (Interrupt occurred)
    [6] TXEMPTY — Masked Transmit FIFO Empty event.
      0=CLR (Interrupt did not occur); 1=SET (Interrupt occurred)
    [5] TX — Masked Transmit FIFO event. This interrupt is set if the selected Transmit FIFO level has been reached.
      0=CLR (Interrupt did not occur); 1=SET (Interrupt occurred)
    [4] TXFIFO_UNF — TX FIFO underflow interrupt
      0=CLR (Interrupt did not occur); 1=SET (Interrupt occurred)
    [3] RXFULL — RX FIFO Full Interrupt
      0=CLR (Interrupt did not occur); 1=SET (Interrupt occurred)
    [2] RX — Masked Receive Event
      0=CLR (Interrupt did not occur); 1=SET (Interrupt occurred)
    [1] RXFIFO_OVF — Masked RXFIFO overflow event. This interrupt is set if an RX FIFO overflow has been detected.
      0=CLR (Interrupt did not occur); 1=SET (Interrupt occurred)
    [0] PER — Masked Parity error event: this bit if a Parity error has been detected
      0=CLR (Interrupt did not occur); 1=SET (Interrupt occurred)
  0x20 SPGSS1_UC5_SPI_IPSTANDARD_CPU_INT_ISET — Interrupt set
    [16] DMA_DONE_TX — Set DMA Done on TX Event Channel Interrupt
      0=NO_EFFECT (Interrupt disabled); 1=SET (Set Interrupt)
    [15] DMA_DONE_RX — Set DMA Done on RX Event Channel Interrupt
      0=NO_EFFECT (Interrupt disabled); 1=SET (Set Interrupt)
    [8] IDLE — Set SPI IDLE mode event.
      0=NO_EFFECT (Writing 0 has no effect); 1=SET (Set Interrupt)
    [6] TXEMPTY — Set Transmit FIFO Empty event.
      0=NO_EFFECT (Writing 0 has no effect); 1=SET (Set Interrupt)
    [5] TX — Set Transmit event.
      0=NO_EFFECT (Writing 0 has no effect); 1=SET (Set Interrupt)
    [4] TXFIFO_UNF — Set TX FIFO Underflow Event
      0=NO_EFFECT (Writing has no effect); 1=SET (Set interrupt)
    [3] RXFULL — Set RX FIFO Full Event
      0=NO_EFFECT (Writing has no effect); 1=SET (Set Interrupt)
    [2] RX — Set Receive event.
      0=NO_EFFECT (Writing 0 has no effect); 1=SET (Set Interrupt)
    [1] RXFIFO_OVF — Set RXFIFO overflow event.
      0=NO_EFFECT (Writing 0 has no effect); 1=SET (Set Interrupt)
    [0] PER — Set Parity error event.
      0=NO_EFFECT (Writing 0 has no effect); 1=SET (Set Interrupt)
  0x28 SPGSS1_UC5_SPI_IPSTANDARD_ICLR — Interrupt clear
    [16] DMA_DONE_TX — Clear DMA Done on TX Event Channel Interrupt
      0=NO_EFFECT (Interrupt disabled); 1=CLR (Clear Interrupt)
    [15] DMA_DONE_RX — Clear DMA Done on RX Event Channel Interrupt
      0=NO_EFFECT (Interrupt disabled); 1=CLR (Clear Interrupt)
    [8] IDLE — Clear SPI IDLE mode event.
      values as SPGSS1_UC0_SPI_IPSTANDARD_CPU_INT.SPGSS1_UC0_SPI_IPSTANDARD_ICLR.IDLE
    [6] TXEMPTY — Clear Transmit FIFO Empty event.
      values as SPGSS1_UC0_SPI_IPSTANDARD_CPU_INT.SPGSS1_UC0_SPI_IPSTANDARD_ICLR.IDLE
    [5] TX — Clear Transmit event.
      values as SPGSS1_UC0_SPI_IPSTANDARD_CPU_INT.SPGSS1_UC0_SPI_IPSTANDARD_ICLR.IDLE
    [4] TXFIFO_UNF — Clear TXFIFO underflow event
      0=NO_EFFECT (Writing has no effect); 1=CLR (Clear interrupt)
    [3] RXFULL — Clear RX FIFO underflow event
      0=NO_EFFECT (Writing has no effect); 1=CLR (Clear interrupt)
    [2] RX — Clear Receive event.
      values as SPGSS1_UC0_SPI_IPSTANDARD_CPU_INT.SPGSS1_UC0_SPI_IPSTANDARD_ICLR.IDLE
    [1] RXFIFO_OVF — Clear RXFIFO overflow event.
      values as SPGSS1_UC0_SPI_IPSTANDARD_CPU_INT.SPGSS1_UC0_SPI_IPSTANDARD_ICLR.IDLE
    [0] PER — Clear Parity error event.
      values as SPGSS1_UC0_SPI_IPSTANDARD_CPU_INT.SPGSS1_UC0_SPI_IPSTANDARD_ICLR.IDLE
0x6B050 SPGSS1_UC5_SPI_IPSTANDARD_DMA_TRIG_RX group
  0x08 SPGSS1_UC5_SPI_IPSTANDARD_DMA_TRIG_RX_IMASK — Interrupt mask
    [2] RX — Receive FIFO event mask.
      0=CLR (Clear Interrupt Mask); 1=SET (Set Interrupt Mask)
  0x10 SPGSS1_UC5_SPI_IPSTANDARD_DMA_TRIG_RX_RIS — Raw interrupt status
    [2] RX — Receive FIFO event.This interrupt is set if the selected Receive FIFO level has been reached
      0=CLR (Interrupt did not occur); 1=SET (Interrupt occurred)
  0x18 SPGSS1_UC5_SPI_IPSTANDARD_DMA_TRIG_RX_MIS — Masked interrupt status
    [2] RX — Receive FIFO event mask.
      0=CLR (Interrupt did not occur); 1=SET (Interrupt occurred)
  0x20 SPGSS1_UC5_SPI_IPSTANDARD_DMA_TRIG_RX_ISET — Interrupt set
    [2] RX — Set Receive FIFO event.
      0=NO_EFFECT (Writing 0 has no effect); 1=SET (Set Interrupt)
0x6B080 SPGSS1_UC5_SPI_IPSTANDARD_DMA_TRIG_TX group
  0x08 SPGSS1_UC5_SPI_IPSTANDARD_DMA_TRIG_TX_IMASK — Interrupt mask
    fields as SPGSS1_UC0_SPI_IPSTANDARD_DMA_TRIG_TX.SPGSS1_UC0_SPI_IPSTANDARD_DMA_TRIG_TX_IMASK
  0x10 SPGSS1_UC5_SPI_IPSTANDARD_DMA_TRIG_TX_RIS — Raw interrupt status
    fields as SPGSS1_UC0_SPI_IPSTANDARD_DMA_TRIG_TX.SPGSS1_UC0_SPI_IPSTANDARD_DMA_TRIG_TX_RIS
  0x18 SPGSS1_UC5_SPI_IPSTANDARD_DMA_TRIG_TX_MIS — Masked interrupt status
    fields as SPGSS1_UC0_SPI_IPSTANDARD_DMA_TRIG_TX.SPGSS1_UC0_SPI_IPSTANDARD_DMA_TRIG_TX_MIS
  0x20 SPGSS1_UC5_SPI_IPSTANDARD_DMA_TRIG_TX_ISET — Interrupt set
    fields as SPGSS1_UC0_SPI_IPSTANDARD_DMA_TRIG_TX.SPGSS1_UC0_SPI_IPSTANDARD_DMA_TRIG_TX_ISET
0x6B0E4 SPGSS1_UC5_SPI_IPSTANDARD_INTCTL — Interrupt control register
  fields as SPGSS1_UC0_SPI_IPSTANDARD_INTCTL
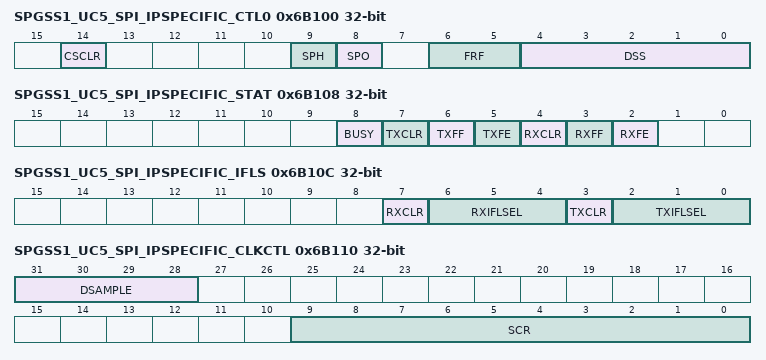
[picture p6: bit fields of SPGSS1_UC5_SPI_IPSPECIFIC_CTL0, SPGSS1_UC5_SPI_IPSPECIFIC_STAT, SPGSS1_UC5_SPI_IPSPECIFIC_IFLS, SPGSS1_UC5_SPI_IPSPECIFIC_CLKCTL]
0x6B100 SPGSS1_UC5_SPI_IPSPECIFIC_CTL0 — SPI control register 0
  [14] CSCLR — Clear shift register counter on CS inactive This bit is relevant only in the peripheral, CTL1.CP=0.
    values as SPGSS1_UC0_SPI_IPSPECIFIC_CTL0.CSCLR
  [9] SPH — CLKOUT phase (Motorola SPI frame format only) This bit selects the clock edge that captures data and enables it to change state. It has the most impact on the first bit transmitted by either permitting or not permitting a clock transition before the first data capture edge.
    values as SPGSS1_UC0_SPI_IPSPECIFIC_CTL0.SPH
  [8] SPO — CLKOUT polarity (Motorola SPI frame format only)
    values as SPGSS1_UC0_SPI_IPSPECIFIC_CTL0.SPO
  [6:5] FRF — Frame format Select
    values as SPGSS1_UC0_SPI_IPSPECIFIC_CTL0.FRF
  [4:0] DSS — Data Size Select. Values 0 - 2 are reserved and shall not be used. 3h = 4_BIT : 4-bit data SPI allows only values up to 16 Bit
    {v}=Data Size Select bits: {v+1} (v=3..15)
0x6B108 SPGSS1_UC5_SPI_IPSPECIFIC_STAT access per field — Status Register
  [8] BUSY rw
    values as SPGSS1_UC0_SPI_IPSPECIFIC_STAT.BUSY
  [7] TXCLR ro — TX FIFO Clear Status
    values as SPGSS1_UC0_SPI_IPSPECIFIC_STAT.TXCLR
  [6] TXFF ro — Transmit FIFO Full The meaning of this bit depends on the state of the FEN bit in the CTL0 register.
    values as SPGSS1_UC0_SPI_IPSPECIFIC_STAT.TXFF
  [5] TXFE rw — Transmit FIFO empty.
    values as SPGSS1_UC0_SPI_IPSPECIFIC_STAT.TXFE
  [4] RXCLR ro — RX FIFO Clear Status
    values as SPGSS1_UC0_SPI_IPSPECIFIC_STAT.TXCLR
  [3] RXFF ro — Receive FIFO Full The meaning of this bit depends on the state of the FEN bit in the CTL0 register.
    values as SPGSS1_UC0_SPI_IPSPECIFIC_STAT.RXFF
  [2] RXFE rw — Receive FIFO empty.
    values as SPGSS1_UC0_SPI_IPSPECIFIC_STAT.RXFE
0x6B10C SPGSS1_UC5_SPI_IPSPECIFIC_IFLS — Interrupt FIFO Level Select Register
  fields as SPGSS1_UC5_I2CT_IPSPECIFIC_IFLS
0x6B110 SPGSS1_UC5_SPI_IPSPECIFIC_CLKCTL — Clock prescaler and divider register.
  fields as SPGSS1_UC0_SPI_IPSPECIFIC_CLKCTL
0x6B120 SPGSS1_UC5_SPI_IPSPECIFIC_TXDATA — TXDATA Register
  fields as SPGSS1_UC0_SPI_IPSPECIFIC_TXDATA
0x6B124 SPGSS1_UC5_SPI_IPSPECIFIC_RXDATA ro — RXDATA Register
  fields as SPGSS1_UC0_SPI_IPSPECIFIC_RXDATA
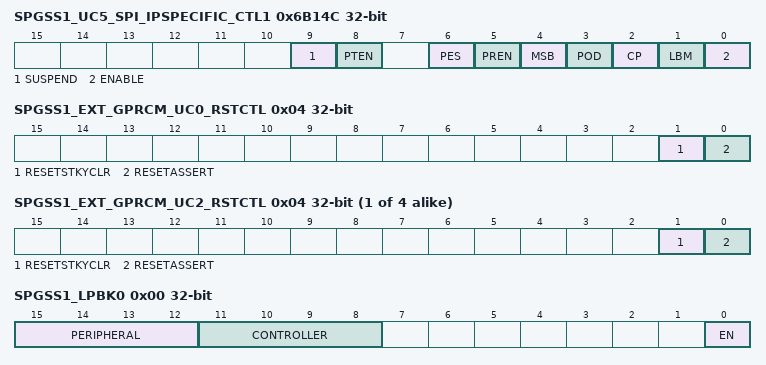
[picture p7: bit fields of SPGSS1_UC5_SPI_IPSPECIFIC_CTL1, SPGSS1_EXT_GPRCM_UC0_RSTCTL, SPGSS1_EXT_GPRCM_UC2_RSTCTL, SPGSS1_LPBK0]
0x6B14C SPGSS1_UC5_SPI_IPSPECIFIC_CTL1 — SPI control register 1
  [9] SUSPEND — Suspend external communication
    values as SPGSS1_UC0_SPI_IPSPECIFIC_CTL1.SUSPEND
  [8] PTEN — Parity transmit enable If enabled, parity transmission will be done for both controller and peripheral modes.
    values as SPGSS1_UC0_SPI_IPSPECIFIC_CTL1.PTEN
  [6] PES — Even Parity Select
    0=DISABLE (Odd Parity mode); 1=ENABLE (Even Parity mode)
  [5] PREN — Parity receive enable If enabled, parity reception check will be done for both controller and peripheral modes In case of a parity miss-match the parity error flag RIS.PER will be set.
    values as SPGSS1_UC0_SPI_IPSPECIFIC_CTL1.PREN
  [4] MSB — MSB first select. Controls the direction of the receive and transmit shift register.
    0=DISABLE (LSB first); 1=ENABLE (MSB first)
  [3] POD — Peripheral-mode: Data output disabled This bit is relevant only in Peripheral mode. In multiple-peripheral system topologies, SPI controller can broadcast a message to all peripherals, while only one peripheral drives the line. POD can be used by the SPI peripheral to disable driving data on the line.
    values as SPGSS1_UC0_SPI_IPSPECIFIC_CTL1.POD
  [2] CP — Controller or peripheral mode select. This bit can be modified only when SPI is disabled, CTL1.ENABLE=0.
    values as SPGSS1_UC0_SPI_IPSPECIFIC_CTL1.CP
  [1] LBM — Loop back mode
    values as SPGSS1_UC0_SPI_IPSPECIFIC_CTL1.LBM
  [0] ENABLE — SPI enable
    values as SPGSS1_UC0_SPI_IPSPECIFIC_CTL1.ENABLE
0x6BE00 SPGSS1_UC5_SPI_LMGMT_DFT_ATRT_TEST0 — Test 0 Register
  fields as SPGSS1_UC0_SPI_LMGMT_DFT_ATRT_TEST0
0x80800 SPGSS1_EXT_GPRCM_UC0_GPRCM group
  0x00 SPGSS1_EXT_GPRCM_UC0_PWREN — Power enable
    [0] ENABLE — Enable the power
      0=DISABLE (Disable Power); 1=ENABLE (Enable Power)
  0x04 SPGSS1_EXT_GPRCM_UC0_RSTCTL — Reset Control
    [1] RESETSTKYCLR — Clear the RESETSTKY bit in the STAT register
      0=NOP (Writing 0 has no effect); 1=CLR (Clear reset sticky bit)
    [0] RESETASSERT — Assert reset to the peripheral
      0=NOP (Writing 0 has no effect); 1=ASSERT (Assert reset)
  0x08 SPGSS1_EXT_GPRCM_UC0_CLKCFG — Peripheral Clock Configuration Register
    [8] BLOCKASYNC — Async Clock Request is blocked from starting SYSOSC or forcing bus clock to 32MHz
      0=DISABLE (Not block async clock request); 1=ENABLE (Block async clock request)
  0x14 SPGSS1_EXT_GPRCM_UC0_GPRCM_STAT ro — Status Register
    [16] RESETSTKY — This bit indicates, if the peripheral was reset, since this bit was cleared by RESETSTKYCLR in the RSTCTL register
      0=NORES (The peripheral has not been reset since this bit was last cleared by RESETSTKYCLR in the RSTCTL register); 1=RESET (The peripheral was reset since the last bit clear)
{0x80800+0x2000*i} SPGSS1_EXT_GPRCM_UC{i}_GPRCM group (i=2..5)
  0x00 SPGSS1_EXT_GPRCM_UC{i}_PWREN — Power enable
    fields as SPGSS1_EXT_GPRCM_UC0_GPRCM.SPGSS1_EXT_GPRCM_UC0_PWREN
  0x04 SPGSS1_EXT_GPRCM_UC{i}_RSTCTL — Reset Control
    fields as SPGSS1_EXT_GPRCM_UC0_GPRCM.SPGSS1_EXT_GPRCM_UC0_RSTCTL
  0x08 SPGSS1_EXT_GPRCM_UC{i}_CLKCFG — Peripheral Clock Configuration Register
    fields as SPGSS1_EXT_GPRCM_UC0_GPRCM.SPGSS1_EXT_GPRCM_UC0_CLKCFG
  0x14 SPGSS1_EXT_GPRCM_UC{i}_GPRCM_STAT ro — Status Register
    fields as SPGSS1_EXT_GPRCM_UC0_GPRCM.SPGSS1_EXT_GPRCM_UC0_GPRCM_STAT
0x85100 SPGSS1_UC2_IPSPECIFIC_IPMODE — Mode Selection Register
  [1:0] SELECT — Free run control
    0=UART (Default functionality is UART); 1=SPI (SPG in SPI Mode); 2=I2C_CONTROLLER (SPG in I2C Controller Mode); 3=I2C_PERIPHERAL (SPG in I2C Peripheral Mode)
0x87100 SPGSS1_UC3_IPSPECIFIC_IPMODE — Mode Selection Register
  fields as SPGSS1_UC2_IPSPECIFIC_IPMODE
0x8B100 SPGSS1_UC5_IPSPECIFIC_IPMODE — Mode Selection Register
  fields as SPGSS1_UC2_IPSPECIFIC_IPMODE
0xA0120 SPGSS1_UNICOMM_LPBK group
  0x00 SPGSS1_LPBK0 — Loopback between SPG instances User has to ensure that the SPGs looped back have the same underlying IP instantiated; i.e. both UART, both SPI, both I2C, etc.,
    [15:12] PERIPHERAL — Select SPG peripheral for loopback. Signals invovled in loopback based on interface chosen 1. SPI : CS, SCLK, SDI, SDO 2. I2C : SCL, SDA 3. UART : TX, RX
      {v}=SPG{v+1} (SPG responder select for loopback.) (v=0..15)
    [11:8] CONTROLLER — Select SPG controller for loopback. Signals invovled in loopback based on interface chosen 1. SPI : CS, SCLK, SDI, SDO 2. I2C : SCL, SDA 3. UART : TX, RX
      {v}=SPG{v+1} (SPG commander select for loopback.) (v=0..15)
    [0] EN — Loopback enable
      values as SPGSS1_UC0_SPI_IPSTANDARD_CLKSEL.BUSCLK_SEL
0xA01C0 SPGSS1_I2C_PAIR group
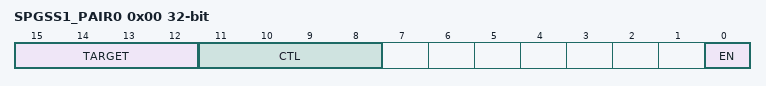
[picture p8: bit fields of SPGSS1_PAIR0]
  0x00 SPGSS1_PAIR0 — Pairing of I2C for MULTI-MASTER/SMBUS applications
    [15:12] TARGET — UNICOMM instance for loopback. This instance will be treated as the target
      {v}=SPG{v+1} (SPG responder select for loopback.) (v=0..15)
    [11:8] CTL — UNICOMM instance for loopback. This instance will be treated as the controller.
      {v}=SPG{v+1} (SPG commander select for loopback.) (v=0..15)
    [0] EN — Enable
      values as SPGSS1_UC0_SPI_IPSTANDARD_CLKSEL.BUSCLK_SEL
0xA0C00 SPGSS1_SPGSS_LMGMT_DFT_ATRT_TEST0 — Test 0 register
  [3:0] DTB_MUX_SEL — This bit field is used to select DTB mux digital output signals.
